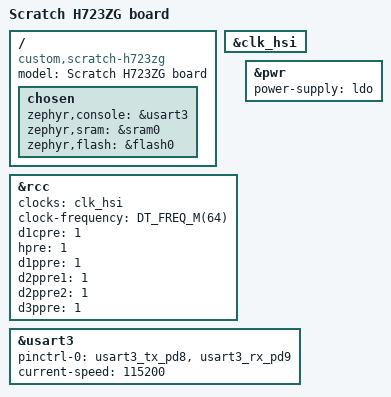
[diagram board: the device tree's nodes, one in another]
/dts-v1/;
#include <st/h7/stm32h723Xg.dtsi>
#include <st/h7/stm32h723zgtx-pinctrl.dtsi>

/ {
	model = "Scratch H723ZG board";
	compatible = "custom,scratch-h723zg";

	chosen {
		zephyr,console = &usart3;
		zephyr,sram = &sram0;
		zephyr,flash = &flash0;
	};
};

&clk_hsi {
	status = "okay";
};

&rcc {
	clocks = <&clk_hsi>;
	clock-frequency = <DT_FREQ_M(64)>;
	d1cpre = <1>;
	hpre = <1>;
	d1ppre = <1>;
	d2ppre1 = <1>;
	d2ppre2 = <1>;
	d3ppre = <1>;
};

&pwr {
	power-supply = "ldo";
};

&usart3 {
	pinctrl-0 = <&usart3_tx_pd8 &usart3_rx_pd9>;
	pinctrl-names = "default";
	current-speed = <115200>;
	status = "okay";
};
